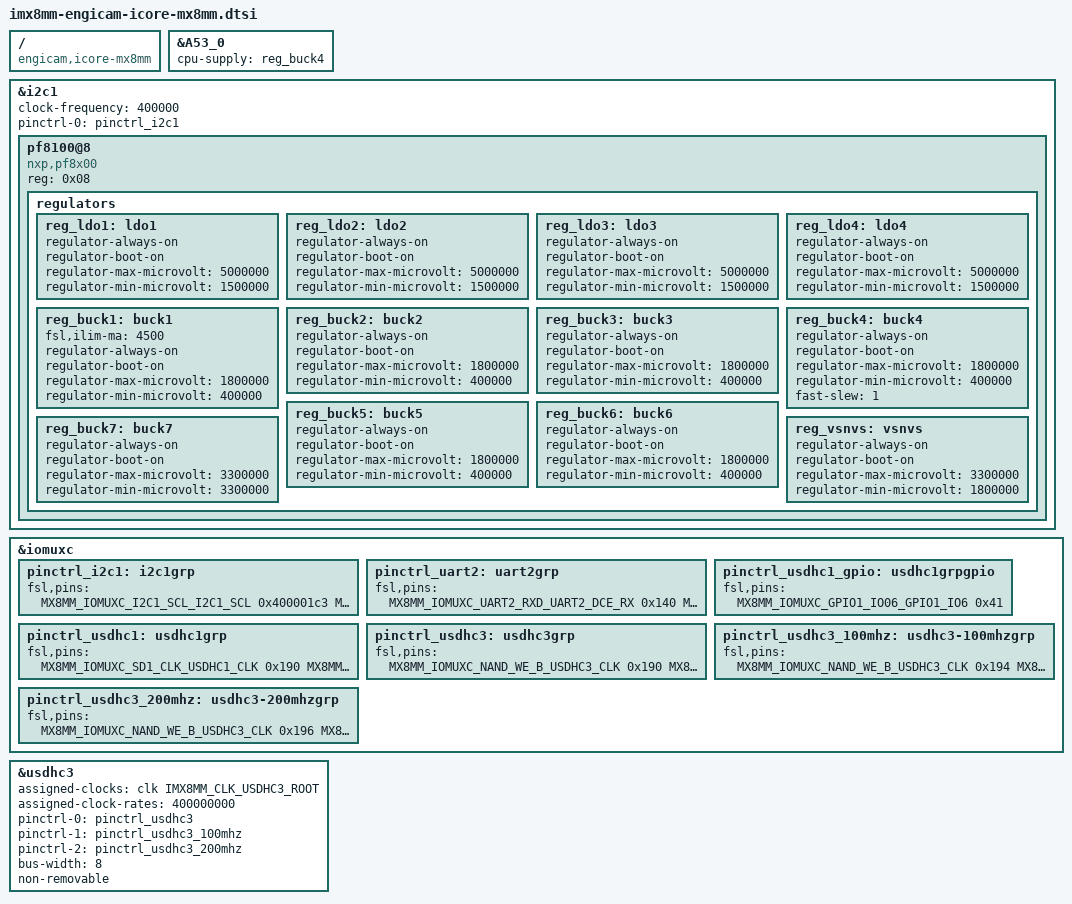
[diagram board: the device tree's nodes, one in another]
// SPDX-License-Identifier: (GPL-2.0+ OR MIT)
/*
 * Copyright (c) 2018 NXP
 * Copyright (c) 2019 Engicam srl
 * Copyright (c) 2020 Amarula Solutons(India)
 */

/ {
	compatible = "engicam,icore-mx8mm", "fsl,imx8mm";
};

&A53_0 {
	cpu-supply = <&reg_buck4>;
};

&i2c1 {
	clock-frequency = <400000>;
	pinctrl-names = "default";
	pinctrl-0 = <&pinctrl_i2c1>;
	status = "okay";

	pf8100@8 {
		compatible = "nxp,pf8x00";
		reg = <0x08>;

		regulators {
			reg_ldo1: ldo1 {
				regulator-always-on;
				regulator-boot-on;
				regulator-max-microvolt = <5000000>;
				regulator-min-microvolt = <1500000>;
			};

			reg_ldo2: ldo2 {
				regulator-always-on;
				regulator-boot-on;
				regulator-max-microvolt = <5000000>;
				regulator-min-microvolt = <1500000>;
			};

			reg_ldo3: ldo3 {
				regulator-always-on;
				regulator-boot-on;
				regulator-max-microvolt = <5000000>;
				regulator-min-microvolt = <1500000>;
			};

			reg_ldo4: ldo4 {
				regulator-always-on;
				regulator-boot-on;
				regulator-max-microvolt = <5000000>;
				regulator-min-microvolt = <1500000>;
			};

			reg_buck1: buck1 {
				fsl,ilim-ma = <4500>;
				regulator-always-on;
				regulator-boot-on;
				regulator-max-microvolt = <1800000>;
				regulator-min-microvolt =  <400000>;
			};

			reg_buck2: buck2 {
				regulator-always-on;
				regulator-boot-on;
				regulator-max-microvolt = <1800000>;
				regulator-min-microvolt =  <400000>;
			};

			reg_buck3: buck3 {
				regulator-always-on;
				regulator-boot-on;
				regulator-max-microvolt = <1800000>;
				regulator-min-microvolt =  <400000>;
			};

			reg_buck4: buck4 {
				regulator-always-on;
				regulator-boot-on;
				regulator-max-microvolt = <1800000>;
				regulator-min-microvolt =  <400000>;
				fast-slew = <1>;
			};

			reg_buck5: buck5 {
				regulator-always-on;
				regulator-boot-on;
				regulator-max-microvolt = <1800000>;
				regulator-min-microvolt =  <400000>;
			};

			reg_buck6: buck6 {
				regulator-always-on;
				regulator-boot-on;
				regulator-max-microvolt = <1800000>;
				regulator-min-microvolt =  <400000>;
			};

			reg_buck7: buck7 {
				regulator-always-on;
				regulator-boot-on;
				regulator-max-microvolt = <3300000>;
				regulator-min-microvolt = <3300000>;
			};

			reg_vsnvs: vsnvs {
				regulator-always-on;
				regulator-boot-on;
				regulator-max-microvolt = <3300000>;
				regulator-min-microvolt = <1800000>;
			};
		};
	};
};

&iomuxc {
	pinctrl_i2c1: i2c1grp {
		fsl,pins = <
			MX8MM_IOMUXC_I2C1_SCL_I2C1_SCL		0x400001c3
			MX8MM_IOMUXC_I2C1_SDA_I2C1_SDA		0x400001c3
		>;
	};

	pinctrl_uart2: uart2grp {
		fsl,pins = <
			MX8MM_IOMUXC_UART2_RXD_UART2_DCE_RX	0x140
			MX8MM_IOMUXC_UART2_TXD_UART2_DCE_TX	0x140
		>;
	};

	pinctrl_usdhc1_gpio: usdhc1grpgpio {
		fsl,pins = <
			MX8MM_IOMUXC_GPIO1_IO06_GPIO1_IO6	0x41
		>;
	};

	pinctrl_usdhc1: usdhc1grp {
		fsl,pins = <
			MX8MM_IOMUXC_SD1_CLK_USDHC1_CLK		0x190
			MX8MM_IOMUXC_SD1_CMD_USDHC1_CMD		0x1d0
			MX8MM_IOMUXC_SD1_DATA0_USDHC1_DATA0	0x1d0
			MX8MM_IOMUXC_SD1_DATA1_USDHC1_DATA1	0x1d0
			MX8MM_IOMUXC_SD1_DATA2_USDHC1_DATA2	0x1d0
			MX8MM_IOMUXC_SD1_DATA3_USDHC1_DATA3	0x1d0
		>;
	};

	pinctrl_usdhc3: usdhc3grp {
		fsl,pins = <
			MX8MM_IOMUXC_NAND_WE_B_USDHC3_CLK               0x190
			MX8MM_IOMUXC_NAND_WP_B_USDHC3_CMD               0x1d0
			MX8MM_IOMUXC_NAND_DATA04_USDHC3_DATA0           0x1d0
			MX8MM_IOMUXC_NAND_DATA05_USDHC3_DATA1           0x1d0
			MX8MM_IOMUXC_NAND_DATA06_USDHC3_DATA2           0x1d0
			MX8MM_IOMUXC_NAND_DATA06_USDHC3_DATA2           0x1d0
			MX8MM_IOMUXC_NAND_DATA07_USDHC3_DATA3           0x1d0
			MX8MM_IOMUXC_NAND_RE_B_USDHC3_DATA4             0x1d0
			MX8MM_IOMUXC_NAND_CE2_B_USDHC3_DATA5            0x1d0
			MX8MM_IOMUXC_NAND_CE3_B_USDHC3_DATA6            0x1d0
			MX8MM_IOMUXC_NAND_CLE_USDHC3_DATA7              0x1d0
			MX8MM_IOMUXC_NAND_CE1_B_USDHC3_STROBE           0x190
		>;
	};

	pinctrl_usdhc3_100mhz: usdhc3-100mhzgrp {
		fsl,pins = <
			MX8MM_IOMUXC_NAND_WE_B_USDHC3_CLK               0x194
			MX8MM_IOMUXC_NAND_WP_B_USDHC3_CMD               0x1d4
			MX8MM_IOMUXC_NAND_DATA04_USDHC3_DATA0           0x1d4
			MX8MM_IOMUXC_NAND_DATA05_USDHC3_DATA1           0x1d4
			MX8MM_IOMUXC_NAND_DATA06_USDHC3_DATA2           0x1d4
			MX8MM_IOMUXC_NAND_DATA07_USDHC3_DATA3           0x1d4
			MX8MM_IOMUXC_NAND_RE_B_USDHC3_DATA4             0x1d4
			MX8MM_IOMUXC_NAND_CE2_B_USDHC3_DATA5            0x1d4
			MX8MM_IOMUXC_NAND_CE3_B_USDHC3_DATA6            0x1d4
			MX8MM_IOMUXC_NAND_CLE_USDHC3_DATA7              0x1d4
			MX8MM_IOMUXC_NAND_CE1_B_USDHC3_STROBE           0x194
		>;
	};

	pinctrl_usdhc3_200mhz: usdhc3-200mhzgrp {
		fsl,pins = <
			MX8MM_IOMUXC_NAND_WE_B_USDHC3_CLK               0x196
			MX8MM_IOMUXC_NAND_WP_B_USDHC3_CMD               0x1d6
			MX8MM_IOMUXC_NAND_DATA04_USDHC3_DATA0           0x1d6
			MX8MM_IOMUXC_NAND_DATA05_USDHC3_DATA1           0x1d6
			MX8MM_IOMUXC_NAND_DATA06_USDHC3_DATA2           0x1d6
			MX8MM_IOMUXC_NAND_DATA07_USDHC3_DATA3           0x1d6
			MX8MM_IOMUXC_NAND_RE_B_USDHC3_DATA4             0x1d6
			MX8MM_IOMUXC_NAND_CE2_B_USDHC3_DATA5            0x1d6
			MX8MM_IOMUXC_NAND_CE3_B_USDHC3_DATA6            0x1d6
			MX8MM_IOMUXC_NAND_CLE_USDHC3_DATA7              0x1d6
			MX8MM_IOMUXC_NAND_CE1_B_USDHC3_STROBE           0x196
		>;
	};
};

/* eMMC */
&usdhc3 {
	assigned-clocks = <&clk IMX8MM_CLK_USDHC3_ROOT>;
	assigned-clock-rates = <400000000>;
	pinctrl-names = "default", "state_100mhz", "state_200mhz";
	pinctrl-0 = <&pinctrl_usdhc3>;
	pinctrl-1 = <&pinctrl_usdhc3_100mhz>;
	pinctrl-2 = <&pinctrl_usdhc3_200mhz>;
	bus-width = <8>;
	non-removable;
	status = "okay";
};
